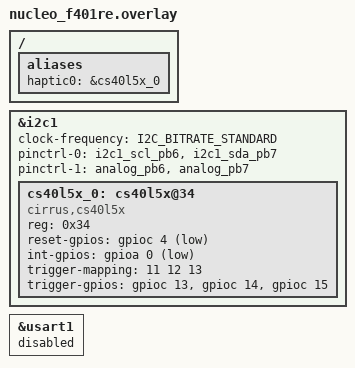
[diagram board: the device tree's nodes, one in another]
/*
 * Copyright (c) 2025 Cirrus Logic, Inc.
 *
 * SPDX-License-Identifier: Apache-2.0
 */

#include <zephyr/dt-bindings/i2c/i2c.h>

/ {
	aliases {
		haptic0 = &cs40l5x_0;
	};
};

&i2c1 {
	status = "okay";

	clock-frequency = <I2C_BITRATE_STANDARD>;

	pinctrl-0 = <&i2c1_scl_pb6 &i2c1_sda_pb7>;
	pinctrl-1 = <&analog_pb6 &analog_pb7>;
	pinctrl-names = "default", "sleep";

	cs40l5x_0: cs40l5x@34 {
		compatible = "cirrus,cs40l5x";
		reg = <0x34>;

		reset-gpios = <&gpioc 4 (GPIO_ACTIVE_LOW | GPIO_PULL_UP)>;
		int-gpios = <&gpioa 0 (GPIO_ACTIVE_LOW | GPIO_PULL_UP)>;

		trigger-mapping = <11 12 13>;
		trigger-gpios = <&gpioc 13 GPIO_PULL_UP>,
				<&gpioc 14 GPIO_PULL_UP>,
				<&gpioc 15 GPIO_PULL_UP>;

		status = "okay";
	};
};

&usart1 {
	status = "disabled";
};
